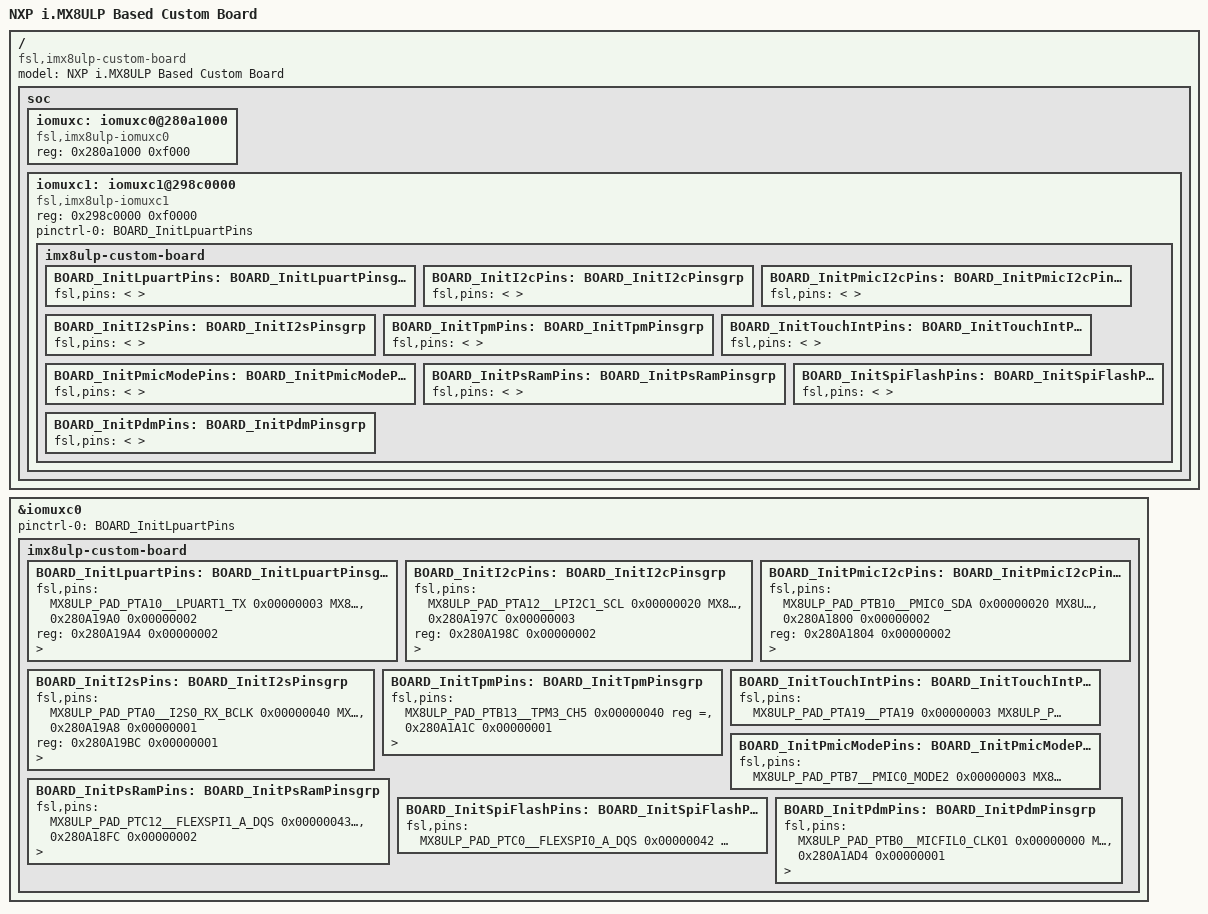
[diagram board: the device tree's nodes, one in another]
/***********************************************************************************************************************
 * This file was generated by the MCUXpresso Config Tools. Any manual edits made to this file
 * will be overwritten if the respective MCUXpresso Config Tools is used to update this file.
 **********************************************************************************************************************/

/*
 * TEXT BELOW IS USED AS SETTING FOR TOOLS *************************************
!!GlobalInfo
product: Pins v14.0
processor: MIMX8UD7xxx10
package_id: MIMX8UD7DVP10
mcu_data: ksdk2_0
processor_version: 14.0.0
pin_labels:
- {pin_num: AH1, pin_signal: PTA5, label: 'Touchscreen reset IO '}
- {pin_num: AF1, pin_signal: PTA6, label: MIPI-DSI Enable IO}
- {pin_num: AJ4, pin_signal: PTA19, label: Touchscreen interrupt IO}
- {pin_num: AE24, pin_signal: PTC23, label: MIPI-CSI2 Power Enable IO}
 * BE CAREFUL MODIFYING THIS COMMENT - IT IS YAML SETTINGS FOR TOOLS ***********
 */


/dts-v1/;

#include "skeleton.dtsi"
#include "imx8ulp-pinfunc.h"

/ {
    model = "NXP i.MX8ULP Based Custom Board";
    compatible = "fsl,imx8ulp-custom-board", "fsl,imx8ulp";

    soc {
        #address-cells = <1>;
        #size-cells = <1>;

        iomuxc: iomuxc0@280a1000 {
            compatible = "fsl,imx8ulp-iomuxc0";
            reg = <0x280a1000 0xf000>;
        };
        iomuxc1: iomuxc1@298c0000 {
            compatible = "fsl,imx8ulp-iomuxc1";
            reg = <0x298c0000 0xf0000>;
        };
    };
};

&iomuxc0 {
    pinctrl-names = "default_iomuxc0";
    pinctrl-0 = <&BOARD_InitLpuartPins>;


    imx8ulp-custom-board {
        BOARD_InitLpuartPins: BOARD_InitLpuartPinsgrp {    /*!< Function assigned for the core: Cortex-M33[cm33] */
/*
 * TEXT BELOW IS USED AS SETTING FOR TOOLS *************************************
BOARD_InitLpuartPins:
- options: {callFromInitBoot: 'true', coreID: cm33}
- pin_list:
  - {pin_num: AH2, peripheral: LPUART1, signal: lpuart_tx, pin_signal: PTA10, PS: UP, PE: ENABLED}
  - {pin_num: AH3, peripheral: LPUART1, signal: lpuart_rx, pin_signal: PTA11, PS: UP, PE: ENABLED}
 * BE CAREFUL MODIFYING THIS COMMENT - IT IS YAML SETTINGS FOR TOOLS ***********
 */
            fsl,pins = <
                MX8ULP_PAD_PTA10__LPUART1_TX               0x00000003
                MX8ULP_PAD_PTA11__LPUART1_RX               0x00000003
            /* Set register IOMUXC0_PSMI0_LPUART1_RX to 0x00000002 */
            reg = <0x280A19A0 0x00000002>;
            /* Set register IOMUXC0_PSMI0_LPUART1_TX to 0x00000002 */
            reg = <0x280A19A4 0x00000002>;
            >;
        };
        BOARD_InitI2cPins: BOARD_InitI2cPinsgrp {          /*!< Function assigned for the core: Cortex-M33[cm33] */
/*
 * TEXT BELOW IS USED AS SETTING FOR TOOLS *************************************
BOARD_InitI2cPins:
- options: {callFromInitBoot: 'true', coreID: cm33}
- pin_list:
  - {pin_num: AH6, peripheral: LPI2C0, signal: lpi2c_scl, pin_signal: PTA16, ODE: OPEN_DRAIN}
  - {pin_num: AD8, peripheral: LPI2C0, signal: lpi2c_sda, pin_signal: PTA17, ODE: OPEN_DRAIN}
  - {pin_num: AE6, peripheral: LPI2C1, signal: lpi2c_scl, pin_signal: PTA12, ODE: OPEN_DRAIN}
  - {pin_num: AJ2, peripheral: LPI2C1, signal: lpi2c_sda, pin_signal: PTA13, ODE: OPEN_DRAIN}
 * BE CAREFUL MODIFYING THIS COMMENT - IT IS YAML SETTINGS FOR TOOLS ***********
 */
            fsl,pins = <
                MX8ULP_PAD_PTA12__LPI2C1_SCL               0x00000020
                MX8ULP_PAD_PTA13__LPI2C1_SDA               0x00000020
                MX8ULP_PAD_PTA16__LPI2C0_SCL               0x00000020
                MX8ULP_PAD_PTA17__LPI2C0_SDA               0x00000020
            /* Set register IOMUXC0_PSMI0_LPI2C0_SCL to 0x00000003 */
            reg = <0x280A197C 0x00000003>;
            /* Set register IOMUXC0_PSMI0_LPI2C0_SDA to 0x00000003 */
            reg = <0x280A1980 0x00000003>;
            /* Set register IOMUXC0_PSMI0_LPI2C1_SCL to 0x00000002 */
            reg = <0x280A1988 0x00000002>;
            /* Set register IOMUXC0_PSMI0_LPI2C1_SDA to 0x00000002 */
            reg = <0x280A198C 0x00000002>;
            >;
        };
        BOARD_InitPmicI2cPins: BOARD_InitPmicI2cPinsgrp {  /*!< Function assigned for the core: Cortex-M33[cm33] */
/*
 * TEXT BELOW IS USED AS SETTING FOR TOOLS *************************************
BOARD_InitPmicI2cPins:
- options: {callFromInitBoot: 'true', coreID: cm33}
- pin_list:
  - {pin_num: AJ14, peripheral: POWERSYS, signal: pmic_scl, pin_signal: PTB11, ODE: OPEN_DRAIN}
  - {pin_num: AH14, peripheral: POWERSYS, signal: pmic_sda, pin_signal: PTB10, ODE: OPEN_DRAIN}
 * BE CAREFUL MODIFYING THIS COMMENT - IT IS YAML SETTINGS FOR TOOLS ***********
 */
            fsl,pins = <
                MX8ULP_PAD_PTB10__PMIC0_SDA                0x00000020
                MX8ULP_PAD_PTB11__PMIC0_SCL                0x00000020
            /* Set register IOMUXC0_PSMI0_PMIC0_SCL to 0x00000002 */
            reg = <0x280A1800 0x00000002>;
            /* Set register IOMUXC0_PSMI0_PMIC0_SDA to 0x00000002 */
            reg = <0x280A1804 0x00000002>;
            >;
        };
        BOARD_InitI2sPins: BOARD_InitI2sPinsgrp {          /*!< Function assigned for the core: Cortex-M33[cm33] */
/*
 * TEXT BELOW IS USED AS SETTING FOR TOOLS *************************************
BOARD_InitI2sPins:
- options: {callFromInitBoot: 'true', coreID: cm33}
- pin_list:
  - {pin_num: AB6, peripheral: I2S0, signal: 'i2s_rxd, 0', pin_signal: PTA2}
  - {pin_num: AD4, peripheral: I2S0, signal: i2s_mclk, pin_signal: PTA4, DSE: HIDRIVE, OBE: ENABLED}
  - {pin_num: AB5, peripheral: I2S0, signal: i2s_rx_bclk, pin_signal: PTA0, DSE: HIDRIVE}
  - {pin_num: AD5, peripheral: I2S0, signal: i2s_rx_fs, pin_signal: PTA1, DSE: HIDRIVE}
  - {pin_num: AF2, peripheral: I2S0, signal: 'i2s_txd, 0', pin_signal: PTA7, DSE: HIDRIVE}
 * BE CAREFUL MODIFYING THIS COMMENT - IT IS YAML SETTINGS FOR TOOLS ***********
 */
            fsl,pins = <
                MX8ULP_PAD_PTA0__I2S0_RX_BCLK              0x00000040
                MX8ULP_PAD_PTA1__I2S0_RX_FS                0x00000040
                MX8ULP_PAD_PTA2__I2S0_RXD0                 0x00000000
                MX8ULP_PAD_PTA4__I2S0_MCLK                 0x00020040
                MX8ULP_PAD_PTA7__I2S0_TXD0                 0x00000040
            /* Set register IOMUXC0_PSMI0_I2S0_RXD0 to 0x00000001 */
            reg = <0x280A19A8 0x00000001>;
            /* Set register IOMUXC0_PSMI0_I2S0_RX_BCLK to 0x00000001 */
            reg = <0x280A19B8 0x00000001>;
            /* Set register IOMUXC0_PSMI0_I2S0_RX_FS to 0x00000001 */
            reg = <0x280A19BC 0x00000001>;
            >;
        };
        BOARD_InitTpmPins: BOARD_InitTpmPinsgrp {          /*!< Function assigned for the core: Cortex-M33[cm33] */
/*
 * TEXT BELOW IS USED AS SETTING FOR TOOLS *************************************
BOARD_InitTpmPins:
- options: {callFromInitBoot: 'true', coreID: cm33}
- pin_list:
  - {pin_num: AF16, peripheral: TPM3, signal: 'tpm_ch, 5', pin_signal: PTB13, PS: DOWN, DSE: HIDRIVE}
 * BE CAREFUL MODIFYING THIS COMMENT - IT IS YAML SETTINGS FOR TOOLS ***********
 */
            fsl,pins = <
                MX8ULP_PAD_PTB13__TPM3_CH5                 0x00000040
            /* Set register IOMUXC0_PSMI0_TPM3_CH5 to 0x00000001 */
            reg = <0x280A1A1C 0x00000001>;
            >;
        };
        BOARD_InitTouchIntPins: BOARD_InitTouchIntPinsgrp {/*!< Function assigned for the core: Cortex-M33[cm33] */
/*
 * TEXT BELOW IS USED AS SETTING FOR TOOLS *************************************
BOARD_InitTouchIntPins:
- options: {callFromInitBoot: 'true', coreID: cm33}
- pin_list:
  - {pin_num: AH1, peripheral: GPIOA, signal: 'pta, 5', pin_signal: PTA5, PS: UP, PE: ENABLED}
  - {pin_num: AF1, peripheral: GPIOA, signal: 'pta, 6', pin_signal: PTA6, PS: UP, PE: ENABLED}
  - {pin_num: AJ4, peripheral: GPIOA, signal: 'pta, 19', pin_signal: PTA19, PS: UP, PE: ENABLED}
  - {pin_num: AF12, peripheral: GPIOB, signal: 'ptb, 5', pin_signal: PTB5, PS: UP, PE: ENABLED}
  - {pin_num: AE24, peripheral: GPIOC, signal: 'ptc, 23', pin_signal: PTC23, PS: UP, PE: ENABLED, SRE: STANDARD}
 * BE CAREFUL MODIFYING THIS COMMENT - IT IS YAML SETTINGS FOR TOOLS ***********
 */
            fsl,pins = <
                MX8ULP_PAD_PTA19__PTA19                    0x00000003
                MX8ULP_PAD_PTA5__PTA5                      0x00000003
                MX8ULP_PAD_PTA6__PTA6                      0x00000003
                MX8ULP_PAD_PTB5__PTB5                      0x00000003
                MX8ULP_PAD_PTC23__PTC23                    0x00000003
            >;
        };
        BOARD_InitPmicModePins: BOARD_InitPmicModePinsgrp {/*!< Function assigned for the core: Cortex-M33[cm33] */
/*
 * TEXT BELOW IS USED AS SETTING FOR TOOLS *************************************
BOARD_InitPmicModePins:
- options: {callFromInitBoot: 'true', coreID: cm33}
- pin_list:
  - {pin_num: AJ12, peripheral: POWERSYS, signal: 'pmic_mode, 0', pin_signal: PTB9, PS: UP, PE: ENABLED}
  - {pin_num: AF14, peripheral: POWERSYS, signal: 'pmic_mode, 1', pin_signal: PTB8, PS: UP, PE: ENABLED}
  - {pin_num: AF13, peripheral: POWERSYS, signal: 'pmic_mode, 2', pin_signal: PTB7, PS: UP, PE: ENABLED}
 * BE CAREFUL MODIFYING THIS COMMENT - IT IS YAML SETTINGS FOR TOOLS ***********
 */
            fsl,pins = <
                MX8ULP_PAD_PTB7__PMIC0_MODE2               0x00000003
                MX8ULP_PAD_PTB8__PMIC0_MODE1               0x00000003
                MX8ULP_PAD_PTB9__PMIC0_MODE0               0x00000003
            >;
        };
        BOARD_InitPsRamPins: BOARD_InitPsRamPinsgrp {      /*!< Function assigned for the core: Cortex-M33[cm33] */
/*
 * TEXT BELOW IS USED AS SETTING FOR TOOLS *************************************
BOARD_InitPsRamPins:
- options: {callFromInitBoot: 'true', coreID: cm33}
- pin_list:
  - {pin_num: AH23, peripheral: FLEXSPI1, signal: flexspi_a_ss0_b, pin_signal: PTC17, PS: UP, PE: ENABLED, SRE: STANDARD, DSE: HIDRIVE}
  - {pin_num: AF22, peripheral: FLEXSPI1, signal: flexspi_a_sclk, pin_signal: PTC18, PS: UP, PE: ENABLED, ODE: PUSH_PULL, DSE: HIDRIVE}
  - {pin_num: AF21, peripheral: FLEXSPI1, signal: flexspi_a_dqs, pin_signal: PTC12, PS: UP, PE: ENABLED, DSE: HIDRIVE}
  - {pin_num: AH20, peripheral: FLEXSPI1, signal: 'flexspi_a_data, 7', pin_signal: PTC13, PS: UP, PE: ENABLED, DSE: HIDRIVE}
  - {pin_num: AE21, peripheral: FLEXSPI1, signal: 'flexspi_a_data, 6', pin_signal: PTC14, PS: UP, PE: ENABLED, DSE: HIDRIVE}
  - {pin_num: AJ22, peripheral: FLEXSPI1, signal: 'flexspi_a_data, 5', pin_signal: PTC15, PS: UP, PE: ENABLED, DSE: HIDRIVE}
  - {pin_num: AD21, peripheral: FLEXSPI1, signal: 'flexspi_a_data, 4', pin_signal: PTC16, PS: UP, PE: ENABLED, DSE: HIDRIVE}
  - {pin_num: AJ24, peripheral: FLEXSPI1, signal: 'flexspi_a_data, 3', pin_signal: PTC19, PS: UP, PE: ENABLED, DSE: HIDRIVE}
  - {pin_num: AE22, peripheral: FLEXSPI1, signal: 'flexspi_a_data, 2', pin_signal: PTC20, PS: UP, PE: ENABLED, DSE: HIDRIVE}
  - {pin_num: AH24, peripheral: FLEXSPI1, signal: 'flexspi_a_data, 1', pin_signal: PTC21, PS: UP, PE: ENABLED, DSE: HIDRIVE}
  - {pin_num: AD22, peripheral: FLEXSPI1, signal: 'flexspi_a_data, 0', pin_signal: PTC22, PS: UP, PE: ENABLED, DSE: HIDRIVE}
 * BE CAREFUL MODIFYING THIS COMMENT - IT IS YAML SETTINGS FOR TOOLS ***********
 */
            fsl,pins = <
                MX8ULP_PAD_PTC12__FLEXSPI1_A_DQS           0x00000043
                MX8ULP_PAD_PTC13__FLEXSPI1_A_DATA7         0x00000043
                MX8ULP_PAD_PTC14__FLEXSPI1_A_DATA6         0x00000043
                MX8ULP_PAD_PTC15__FLEXSPI1_A_DATA5         0x00000043
                MX8ULP_PAD_PTC16__FLEXSPI1_A_DATA4         0x00000043
                MX8ULP_PAD_PTC17__FLEXSPI1_A_SS0_B         0x00000043
                MX8ULP_PAD_PTC18__FLEXSPI1_A_SCLK          0x00000043
                MX8ULP_PAD_PTC19__FLEXSPI1_A_DATA3         0x00000043
                MX8ULP_PAD_PTC20__FLEXSPI1_A_DATA2         0x00000043
                MX8ULP_PAD_PTC21__FLEXSPI1_A_DATA1         0x00000043
                MX8ULP_PAD_PTC22__FLEXSPI1_A_DATA0         0x00000043
            /* Set register IOMUXC0_PSMI0_FLEXSPI1_A_SCLK to 0x00000002 */
            reg = <0x280A18FC 0x00000002>;
            >;
        };
        BOARD_InitSpiFlashPins: BOARD_InitSpiFlashPinsgrp {/*!< Function assigned for the core: Cortex-M33[cm33] */
/*
 * TEXT BELOW IS USED AS SETTING FOR TOOLS *************************************
BOARD_InitSpiFlashPins:
- options: {callFromInitBoot: 'true', coreID: cm33}
- pin_list:
  - {pin_num: AF18, peripheral: FLEXSPI0, signal: flexspi_a_dqs, pin_signal: PTC0, PS: DOWN, PE: ENABLED, DSE: HIDRIVE}
  - {pin_num: AJ16, peripheral: FLEXSPI0, signal: 'flexspi_a_data, 7', pin_signal: PTC1, PS: DOWN, PE: DISABLED, DSE: HIDRIVE}
  - {pin_num: AH22, peripheral: FLEXSPI0, signal: 'flexspi_a_data, 0', pin_signal: PTC10, PS: DOWN, PE: DISABLED, DSE: HIDRIVE}
  - {pin_num: AE17, peripheral: FLEXSPI0, signal: 'flexspi_a_data, 6', pin_signal: PTC2, PS: DOWN, PE: DISABLED, DSE: HIDRIVE}
  - {pin_num: AJ18, peripheral: FLEXSPI0, signal: 'flexspi_a_data, 5', pin_signal: PTC3, PS: DOWN, PE: DISABLED, DSE: HIDRIVE}
  - {pin_num: AF17, peripheral: FLEXSPI0, signal: 'flexspi_a_data, 4', pin_signal: PTC4, PS: DOWN, PE: DISABLED, DSE: HIDRIVE}
  - {pin_num: AH18, peripheral: FLEXSPI0, signal: flexspi_a_ss0_b, pin_signal: PTC5, PS: DOWN, PE: DISABLED, DSE: HIDRIVE}
  - {pin_num: AE18, peripheral: FLEXSPI0, signal: flexspi_a_sclk, pin_signal: PTC6, PS: DOWN, PE: DISABLED, DSE: HIDRIVE}
  - {pin_num: AH19, peripheral: FLEXSPI0, signal: 'flexspi_a_data, 3', pin_signal: PTC7, PS: DOWN, PE: DISABLED, DSE: HIDRIVE}
  - {pin_num: AD18, peripheral: FLEXSPI0, signal: 'flexspi_a_data, 2', pin_signal: PTC8, PS: DOWN, PE: DISABLED, DSE: HIDRIVE}
  - {pin_num: AJ20, peripheral: FLEXSPI0, signal: 'flexspi_a_data, 1', pin_signal: PTC9, PS: DOWN, PE: DISABLED, DSE: HIDRIVE}
 * BE CAREFUL MODIFYING THIS COMMENT - IT IS YAML SETTINGS FOR TOOLS ***********
 */
            fsl,pins = <
                MX8ULP_PAD_PTC0__FLEXSPI0_A_DQS            0x00000042
                MX8ULP_PAD_PTC1__FLEXSPI0_A_DATA7          0x00000040
                MX8ULP_PAD_PTC10__FLEXSPI0_A_DATA0         0x00000040
                MX8ULP_PAD_PTC2__FLEXSPI0_A_DATA6          0x00000040
                MX8ULP_PAD_PTC3__FLEXSPI0_A_DATA5          0x00000040
                MX8ULP_PAD_PTC4__FLEXSPI0_A_DATA4          0x00000040
                MX8ULP_PAD_PTC5__FLEXSPI0_A_SS0_B          0x00000040
                MX8ULP_PAD_PTC6__FLEXSPI0_A_SCLK           0x00000040
                MX8ULP_PAD_PTC7__FLEXSPI0_A_DATA3          0x00000040
                MX8ULP_PAD_PTC8__FLEXSPI0_A_DATA2          0x00000040
                MX8ULP_PAD_PTC9__FLEXSPI0_A_DATA1          0x00000040
            >;
        };
        BOARD_InitPdmPins: BOARD_InitPdmPinsgrp {          /*!< Function assigned for the core: Cortex-M33[cm33] */
/*
 * TEXT BELOW IS USED AS SETTING FOR TOOLS *************************************
BOARD_InitPdmPins:
- options: {callFromInitBoot: 'true', coreID: cm33}
- pin_list:
  - {pin_num: AD12, peripheral: MICFIL0, signal: 'micfil_clk, 01', pin_signal: PTB0}
  - {pin_num: AH11, peripheral: MICFIL0, signal: 'micfil_data, 01', pin_signal: PTB1, PS: UP, PE: ENABLED}
 * BE CAREFUL MODIFYING THIS COMMENT - IT IS YAML SETTINGS FOR TOOLS ***********
 */
            fsl,pins = <
                MX8ULP_PAD_PTB0__MICFIL0_CLK01             0x00000000
                MX8ULP_PAD_PTB1__MICFIL0_DATA01            0x00000003
            /* Set register IOMUXC0_PSMI0_MICFIL0_DATA01 to 0x00000001 */
            reg = <0x280A1AD4 0x00000001>;
            >;
        };
    };
};

&iomuxc1 {
    pinctrl-names = "default_iomuxc1";
    pinctrl-0 = <&BOARD_InitLpuartPins>;


    imx8ulp-custom-board {
        BOARD_InitLpuartPins: BOARD_InitLpuartPinsgrp {    /*!< Function assigned for the core: Cortex-M33[cm33] */
/*
 * TEXT BELOW IS USED AS SETTING FOR TOOLS *************************************
BOARD_InitLpuartPins:
- options: {callFromInitBoot: 'true', coreID: cm33}
- pin_list:
  - {pin_num: AH2, peripheral: LPUART1, signal: lpuart_tx, pin_signal: PTA10, PS: UP, PE: ENABLED}
  - {pin_num: AH3, peripheral: LPUART1, signal: lpuart_rx, pin_signal: PTA11, PS: UP, PE: ENABLED}
 * BE CAREFUL MODIFYING THIS COMMENT - IT IS YAML SETTINGS FOR TOOLS ***********
 */
            fsl,pins = <
            >;
        };
        BOARD_InitI2cPins: BOARD_InitI2cPinsgrp {          /*!< Function assigned for the core: Cortex-M33[cm33] */
/*
 * TEXT BELOW IS USED AS SETTING FOR TOOLS *************************************
BOARD_InitI2cPins:
- options: {callFromInitBoot: 'true', coreID: cm33}
- pin_list:
  - {pin_num: AH6, peripheral: LPI2C0, signal: lpi2c_scl, pin_signal: PTA16, ODE: OPEN_DRAIN}
  - {pin_num: AD8, peripheral: LPI2C0, signal: lpi2c_sda, pin_signal: PTA17, ODE: OPEN_DRAIN}
  - {pin_num: AE6, peripheral: LPI2C1, signal: lpi2c_scl, pin_signal: PTA12, ODE: OPEN_DRAIN}
  - {pin_num: AJ2, peripheral: LPI2C1, signal: lpi2c_sda, pin_signal: PTA13, ODE: OPEN_DRAIN}
 * BE CAREFUL MODIFYING THIS COMMENT - IT IS YAML SETTINGS FOR TOOLS ***********
 */
            fsl,pins = <
            >;
        };
        BOARD_InitPmicI2cPins: BOARD_InitPmicI2cPinsgrp {  /*!< Function assigned for the core: Cortex-M33[cm33] */
/*
 * TEXT BELOW IS USED AS SETTING FOR TOOLS *************************************
BOARD_InitPmicI2cPins:
- options: {callFromInitBoot: 'true', coreID: cm33}
- pin_list:
  - {pin_num: AJ14, peripheral: POWERSYS, signal: pmic_scl, pin_signal: PTB11, ODE: OPEN_DRAIN}
  - {pin_num: AH14, peripheral: POWERSYS, signal: pmic_sda, pin_signal: PTB10, ODE: OPEN_DRAIN}
 * BE CAREFUL MODIFYING THIS COMMENT - IT IS YAML SETTINGS FOR TOOLS ***********
 */
            fsl,pins = <
            >;
        };
        BOARD_InitI2sPins: BOARD_InitI2sPinsgrp {          /*!< Function assigned for the core: Cortex-M33[cm33] */
/*
 * TEXT BELOW IS USED AS SETTING FOR TOOLS *************************************
BOARD_InitI2sPins:
- options: {callFromInitBoot: 'true', coreID: cm33}
- pin_list:
  - {pin_num: AB6, peripheral: I2S0, signal: 'i2s_rxd, 0', pin_signal: PTA2}
  - {pin_num: AD4, peripheral: I2S0, signal: i2s_mclk, pin_signal: PTA4, DSE: HIDRIVE, OBE: ENABLED}
  - {pin_num: AB5, peripheral: I2S0, signal: i2s_rx_bclk, pin_signal: PTA0, DSE: HIDRIVE}
  - {pin_num: AD5, peripheral: I2S0, signal: i2s_rx_fs, pin_signal: PTA1, DSE: HIDRIVE}
  - {pin_num: AF2, peripheral: I2S0, signal: 'i2s_txd, 0', pin_signal: PTA7, DSE: HIDRIVE}
 * BE CAREFUL MODIFYING THIS COMMENT - IT IS YAML SETTINGS FOR TOOLS ***********
 */
            fsl,pins = <
            >;
        };
        BOARD_InitTpmPins: BOARD_InitTpmPinsgrp {          /*!< Function assigned for the core: Cortex-M33[cm33] */
/*
 * TEXT BELOW IS USED AS SETTING FOR TOOLS *************************************
BOARD_InitTpmPins:
- options: {callFromInitBoot: 'true', coreID: cm33}
- pin_list:
  - {pin_num: AF16, peripheral: TPM3, signal: 'tpm_ch, 5', pin_signal: PTB13, PS: DOWN, DSE: HIDRIVE}
 * BE CAREFUL MODIFYING THIS COMMENT - IT IS YAML SETTINGS FOR TOOLS ***********
 */
            fsl,pins = <
            >;
        };
        BOARD_InitTouchIntPins: BOARD_InitTouchIntPinsgrp {/*!< Function assigned for the core: Cortex-M33[cm33] */
/*
 * TEXT BELOW IS USED AS SETTING FOR TOOLS *************************************
BOARD_InitTouchIntPins:
- options: {callFromInitBoot: 'true', coreID: cm33}
- pin_list:
  - {pin_num: AH1, peripheral: GPIOA, signal: 'pta, 5', pin_signal: PTA5, PS: UP, PE: ENABLED}
  - {pin_num: AF1, peripheral: GPIOA, signal: 'pta, 6', pin_signal: PTA6, PS: UP, PE: ENABLED}
  - {pin_num: AJ4, peripheral: GPIOA, signal: 'pta, 19', pin_signal: PTA19, PS: UP, PE: ENABLED}
  - {pin_num: AF12, peripheral: GPIOB, signal: 'ptb, 5', pin_signal: PTB5, PS: UP, PE: ENABLED}
  - {pin_num: AE24, peripheral: GPIOC, signal: 'ptc, 23', pin_signal: PTC23, PS: UP, PE: ENABLED, SRE: STANDARD}
 * BE CAREFUL MODIFYING THIS COMMENT - IT IS YAML SETTINGS FOR TOOLS ***********
 */
            fsl,pins = <
            >;
        };
        BOARD_InitPmicModePins: BOARD_InitPmicModePinsgrp {/*!< Function assigned for the core: Cortex-M33[cm33] */
/*
 * TEXT BELOW IS USED AS SETTING FOR TOOLS *************************************
BOARD_InitPmicModePins:
- options: {callFromInitBoot: 'true', coreID: cm33}
- pin_list:
  - {pin_num: AJ12, peripheral: POWERSYS, signal: 'pmic_mode, 0', pin_signal: PTB9, PS: UP, PE: ENABLED}
  - {pin_num: AF14, peripheral: POWERSYS, signal: 'pmic_mode, 1', pin_signal: PTB8, PS: UP, PE: ENABLED}
  - {pin_num: AF13, peripheral: POWERSYS, signal: 'pmic_mode, 2', pin_signal: PTB7, PS: UP, PE: ENABLED}
 * BE CAREFUL MODIFYING THIS COMMENT - IT IS YAML SETTINGS FOR TOOLS ***********
 */
            fsl,pins = <
            >;
        };
        BOARD_InitPsRamPins: BOARD_InitPsRamPinsgrp {      /*!< Function assigned for the core: Cortex-M33[cm33] */
/*
 * TEXT BELOW IS USED AS SETTING FOR TOOLS *************************************
BOARD_InitPsRamPins:
- options: {callFromInitBoot: 'true', coreID: cm33}
- pin_list:
  - {pin_num: AH23, peripheral: FLEXSPI1, signal: flexspi_a_ss0_b, pin_signal: PTC17, PS: UP, PE: ENABLED, SRE: STANDARD, DSE: HIDRIVE}
  - {pin_num: AF22, peripheral: FLEXSPI1, signal: flexspi_a_sclk, pin_signal: PTC18, PS: UP, PE: ENABLED, ODE: PUSH_PULL, DSE: HIDRIVE}
  - {pin_num: AF21, peripheral: FLEXSPI1, signal: flexspi_a_dqs, pin_signal: PTC12, PS: UP, PE: ENABLED, DSE: HIDRIVE}
  - {pin_num: AH20, peripheral: FLEXSPI1, signal: 'flexspi_a_data, 7', pin_signal: PTC13, PS: UP, PE: ENABLED, DSE: HIDRIVE}
  - {pin_num: AE21, peripheral: FLEXSPI1, signal: 'flexspi_a_data, 6', pin_signal: PTC14, PS: UP, PE: ENABLED, DSE: HIDRIVE}
  - {pin_num: AJ22, peripheral: FLEXSPI1, signal: 'flexspi_a_data, 5', pin_signal: PTC15, PS: UP, PE: ENABLED, DSE: HIDRIVE}
  - {pin_num: AD21, peripheral: FLEXSPI1, signal: 'flexspi_a_data, 4', pin_signal: PTC16, PS: UP, PE: ENABLED, DSE: HIDRIVE}
  - {pin_num: AJ24, peripheral: FLEXSPI1, signal: 'flexspi_a_data, 3', pin_signal: PTC19, PS: UP, PE: ENABLED, DSE: HIDRIVE}
  - {pin_num: AE22, peripheral: FLEXSPI1, signal: 'flexspi_a_data, 2', pin_signal: PTC20, PS: UP, PE: ENABLED, DSE: HIDRIVE}
  - {pin_num: AH24, peripheral: FLEXSPI1, signal: 'flexspi_a_data, 1', pin_signal: PTC21, PS: UP, PE: ENABLED, DSE: HIDRIVE}
  - {pin_num: AD22, peripheral: FLEXSPI1, signal: 'flexspi_a_data, 0', pin_signal: PTC22, PS: UP, PE: ENABLED, DSE: HIDRIVE}
 * BE CAREFUL MODIFYING THIS COMMENT - IT IS YAML SETTINGS FOR TOOLS ***********
 */
            fsl,pins = <
            >;
        };
        BOARD_InitSpiFlashPins: BOARD_InitSpiFlashPinsgrp {/*!< Function assigned for the core: Cortex-M33[cm33] */
/*
 * TEXT BELOW IS USED AS SETTING FOR TOOLS *************************************
BOARD_InitSpiFlashPins:
- options: {callFromInitBoot: 'true', coreID: cm33}
- pin_list:
  - {pin_num: AF18, peripheral: FLEXSPI0, signal: flexspi_a_dqs, pin_signal: PTC0, PS: DOWN, PE: ENABLED, DSE: HIDRIVE}
  - {pin_num: AJ16, peripheral: FLEXSPI0, signal: 'flexspi_a_data, 7', pin_signal: PTC1, PS: DOWN, PE: DISABLED, DSE: HIDRIVE}
  - {pin_num: AH22, peripheral: FLEXSPI0, signal: 'flexspi_a_data, 0', pin_signal: PTC10, PS: DOWN, PE: DISABLED, DSE: HIDRIVE}
  - {pin_num: AE17, peripheral: FLEXSPI0, signal: 'flexspi_a_data, 6', pin_signal: PTC2, PS: DOWN, PE: DISABLED, DSE: HIDRIVE}
  - {pin_num: AJ18, peripheral: FLEXSPI0, signal: 'flexspi_a_data, 5', pin_signal: PTC3, PS: DOWN, PE: DISABLED, DSE: HIDRIVE}
  - {pin_num: AF17, peripheral: FLEXSPI0, signal: 'flexspi_a_data, 4', pin_signal: PTC4, PS: DOWN, PE: DISABLED, DSE: HIDRIVE}
  - {pin_num: AH18, peripheral: FLEXSPI0, signal: flexspi_a_ss0_b, pin_signal: PTC5, PS: DOWN, PE: DISABLED, DSE: HIDRIVE}
  - {pin_num: AE18, peripheral: FLEXSPI0, signal: flexspi_a_sclk, pin_signal: PTC6, PS: DOWN, PE: DISABLED, DSE: HIDRIVE}
  - {pin_num: AH19, peripheral: FLEXSPI0, signal: 'flexspi_a_data, 3', pin_signal: PTC7, PS: DOWN, PE: DISABLED, DSE: HIDRIVE}
  - {pin_num: AD18, peripheral: FLEXSPI0, signal: 'flexspi_a_data, 2', pin_signal: PTC8, PS: DOWN, PE: DISABLED, DSE: HIDRIVE}
  - {pin_num: AJ20, peripheral: FLEXSPI0, signal: 'flexspi_a_data, 1', pin_signal: PTC9, PS: DOWN, PE: DISABLED, DSE: HIDRIVE}
 * BE CAREFUL MODIFYING THIS COMMENT - IT IS YAML SETTINGS FOR TOOLS ***********
 */
            fsl,pins = <
            >;
        };
        BOARD_InitPdmPins: BOARD_InitPdmPinsgrp {          /*!< Function assigned for the core: Cortex-M33[cm33] */
/*
 * TEXT BELOW IS USED AS SETTING FOR TOOLS *************************************
BOARD_InitPdmPins:
- options: {callFromInitBoot: 'true', coreID: cm33}
- pin_list:
  - {pin_num: AD12, peripheral: MICFIL0, signal: 'micfil_clk, 01', pin_signal: PTB0}
  - {pin_num: AH11, peripheral: MICFIL0, signal: 'micfil_data, 01', pin_signal: PTB1, PS: UP, PE: ENABLED}
 * BE CAREFUL MODIFYING THIS COMMENT - IT IS YAML SETTINGS FOR TOOLS ***********
 */
            fsl,pins = <
            >;
        };
    };
};

/***********************************************************************************************************************
 * EOF
 **********************************************************************************************************************/
